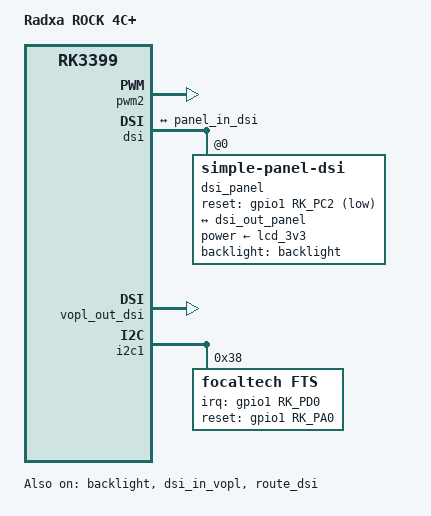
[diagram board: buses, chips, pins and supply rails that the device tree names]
/dts-v1/;
/plugin/;

#include <dt-bindings/gpio/gpio.h>
#include <dt-bindings/pinctrl/rockchip.h>
#include <dt-bindings/display/drm_mipi_dsi.h>
#include <dt-bindings/interrupt-controller/irq.h>

/ {
	model = "Radxa ROCK 4C+";
	compatible = "radxa,rock-4c-plus", "rockchip,rk3399";

	fragment@0 {
		target = <&backlight>;

		__overlay__ {
			status = "okay";
		};
	};

	fragment@1 {
		target = <&pwm2>;

		__overlay__ {
			status = "okay";
		};
	};

	fragment@2 {
		target = <&dsi>;

		__overlay__ {
			status = "okay";
			rockchip,lane-rate = <480>;
			#address-cells = <1>;
			#size-cells = <0>;

			ports {
				#address-cells = <1>;
				#size-cells = <0>;

				port@1 {
					reg = <1>;
					dsi_out_panel: endpoint {
						remote-endpoint = <&panel_in_dsi>;
					};
				};
			};

			dsi_panel: dsi-panel@0 {
				status = "okay";

				compatible = "simple-panel-dsi";
				reg = <0>;

				backlight = <&backlight>;
				power-supply = <&lcd_3v3>;

				reset-gpios = <&gpio1 RK_PC2 GPIO_ACTIVE_LOW>;

				pinctrl-names = "default";
				pinctrl-0 = <&lcd_panel_reset>;

				prepare-delay-ms = <120>;
				reset-delay-ms = <120>;
				init-delay-ms = <120>;
				enable-delay-ms = <100>;
				disable-delay-ms = <120>;
				unprepare-delay-ms = <120>;

				width-mm = <62>;
				height-mm = <110>;

				dsi,flags = <(MIPI_DSI_MODE_VIDEO | MIPI_DSI_MODE_VIDEO_BURST |
						MIPI_DSI_MODE_LPM | MIPI_DSI_MODE_EOT_PACKET)>;
				dsi,format = <MIPI_DSI_FMT_RGB888>;
				dsi,lanes = <4>;

				panel-init-sequence = [
					15 00 02 E0 00
					15 00 02 E1 93
					15 00 02 E2 65
					15 00 02 E3 F8
					15 00 02 80 03
					15 00 02 E0 01
					15 00 02 00 00
					15 00 02 01 3B
					15 00 02 0C 74
					15 00 02 17 00
					15 00 02 18 AF
					15 00 02 19 00
					15 00 02 1A 00
					15 00 02 1B AF
					15 00 02 1C 00
					15 00 02 35 26
					15 00 02 37 09
					15 00 02 38 04
					15 00 02 39 00
					15 00 02 3A 01
					15 00 02 3C 78
					15 00 02 3D FF
					15 00 02 3E FF
					15 00 02 3F 7F
					15 00 02 40 06
					15 00 02 41 A0
					15 00 02 42 81
					15 00 02 43 14
					15 00 02 44 23
					15 00 02 45 28
					15 00 02 55 02
					15 00 02 57 69
					15 00 02 59 0A
					15 00 02 5A 2A
					15 00 02 5B 17
					15 00 02 5D 7F
					15 00 02 5E 6B
					15 00 02 5F 5C
					15 00 02 60 4F
					15 00 02 61 4D
					15 00 02 62 3F
					15 00 02 63 42
					15 00 02 64 2B
					15 00 02 65 44
					15 00 02 66 43
					15 00 02 67 43
					15 00 02 68 63
					15 00 02 69 52
					15 00 02 6A 5A
					15 00 02 6B 4F
					15 00 02 6C 4E
					15 00 02 6D 20
					15 00 02 6E 0F
					15 00 02 6F 00
					15 00 02 70 7F
					15 00 02 71 6B
					15 00 02 72 5C
					15 00 02 73 4F
					15 00 02 74 4D
					15 00 02 75 3F
					15 00 02 76 42
					15 00 02 77 2B
					15 00 02 78 44
					15 00 02 79 43
					15 00 02 7A 43
					15 00 02 7B 63
					15 00 02 7C 52
					15 00 02 7D 5A
					15 00 02 7E 4F
					15 00 02 7F 4E
					15 00 02 80 20
					15 00 02 81 0F
					15 00 02 82 00
					15 00 02 E0 02
					15 00 02 00 02
					15 00 02 01 02
					15 00 02 02 00
					15 00 02 03 00
					15 00 02 04 1E
					15 00 02 05 1E
					15 00 02 06 1F
					15 00 02 07 1F
					15 00 02 08 1F
					15 00 02 09 17
					15 00 02 0A 17
					15 00 02 0B 37
					15 00 02 0C 37
					15 00 02 0D 47
					15 00 02 0E 47
					15 00 02 0F 45
					15 00 02 10 45
					15 00 02 11 4B
					15 00 02 12 4B
					15 00 02 13 49
					15 00 02 14 49
					15 00 02 15 1F
					15 00 02 16 01
					15 00 02 17 01
					15 00 02 18 00
					15 00 02 19 00
					15 00 02 1A 1E
					15 00 02 1B 1E
					15 00 02 1C 1F
					15 00 02 1D 1F
					15 00 02 1E 1F
					15 00 02 1F 17
					15 00 02 20 17
					15 00 02 21 37
					15 00 02 22 37
					15 00 02 23 46
					15 00 02 24 46
					15 00 02 25 44
					15 00 02 26 44
					15 00 02 27 4A
					15 00 02 28 4A
					15 00 02 29 48
					15 00 02 2A 48
					15 00 02 2B 1F
					15 00 02 2C 01
					15 00 02 2D 01
					15 00 02 2E 00
					15 00 02 2F 00
					15 00 02 30 1F
					15 00 02 31 1F
					15 00 02 32 1E
					15 00 02 33 1E
					15 00 02 34 1F
					15 00 02 35 17
					15 00 02 36 17
					15 00 02 37 37
					15 00 02 38 37
					15 00 02 39 08
					15 00 02 3A 08
					15 00 02 3B 0A
					15 00 02 3C 0A
					15 00 02 3D 04
					15 00 02 3E 04
					15 00 02 3F 06
					15 00 02 40 06
					15 00 02 41 1F
					15 00 02 42 02
					15 00 02 43 02
					15 00 02 44 00
					15 00 02 45 00
					15 00 02 46 1F
					15 00 02 47 1F
					15 00 02 48 1E
					15 00 02 49 1E
					15 00 02 4A 1F
					15 00 02 4B 17
					15 00 02 4C 17
					15 00 02 4D 37
					15 00 02 4E 37
					15 00 02 4F 09
					15 00 02 50 09
					15 00 02 51 0B
					15 00 02 52 0B
					15 00 02 53 05
					15 00 02 54 05
					15 00 02 55 07
					15 00 02 56 07
					15 00 02 57 1F
					15 00 02 58 40
					15 00 02 5B 30
					15 00 02 5C 16
					15 00 02 5D 34
					15 00 02 5E 05
					15 00 02 5F 02
					15 00 02 63 00
					15 00 02 64 6A
					15 00 02 67 73
					15 00 02 68 1D
					15 00 02 69 08
					15 00 02 6A 6A
					15 00 02 6B 08
					15 00 02 6C 00
					15 00 02 6D 00
					15 00 02 6E 00
					15 00 02 6F 88
					15 00 02 75 FF
					15 00 02 77 DD
					15 00 02 78 3F
					15 00 02 79 15
					15 00 02 7A 17
					15 00 02 7D 14
					15 00 02 7E 82
					15 00 02 E0 04
					15 00 02 00 0E
					15 00 02 02 B3
					15 00 02 09 61
					15 00 02 0E 48
					15 00 02 E0 00
					15 00 02 E6 02
					15 00 02 E7 0C
					05 78 01 11
					05 14 01 29
				];

				panel-exit-sequence = [
					05 14 01 28
					05 78 01 10
				];

				display-timings {
					native-mode = <&timing0>;
					timing0: timing0 {
						clock-frequency = <67000000>;
						hactive = <800>;
						vactive = <1280>;

						vback-porch = <20>;
						vfront-porch = <20>;

						hback-porch = <20>;
						hfront-porch = <40>;

						hsync-len = <18>;
						vsync-len = <4>;

						vsync-active = <0>;
						hsync-active = <0>;
						de-active = <0>;
						pixelclk-active = <0>;
					};
				};

				ports {
					#address-cells = <1>;
					#size-cells = <0>;

					port@0 {
						reg = <0>;
						panel_in_dsi: endpoint {
							remote-endpoint = <&dsi_out_panel>;
						};
					};
				};
			};
		};
	};

	fragment@3 {
		target = <&vopl_out_dsi>;

		__overlay__ {
			status = "okay";
		};
	};

	fragment@4 {
		target = <&dsi_in_vopl>;

		__overlay__ {
			status = "okay";
		};
	};

	fragment@5 {
		target = <&route_dsi>;

		__overlay__ {
			status = "okay";
			connect = <&vopl_out_dsi>;
		};
	};

	fragment@6 {
		target = <&i2c1>;

		__overlay__ {
			status = "okay";
			#address-cells = <1>;
			#size-cells = <0>;

			focaltech: focaltech@38 {
				status = "okay";
				compatible = "focaltech,fts";
				reg = <0x38>;
				pinctrl-names = "default";
				pinctrl-0 = <&touch_gpio>;
				focaltech,irq-gpio = <&gpio1 RK_PD0 IRQ_TYPE_LEVEL_LOW>;
				focaltech,reset-gpio = <&gpio1 RK_PA0 GPIO_ACTIVE_HIGH>;
				focaltech,have-key = <0>;
				focaltech,key-number = <3>;
				focaltech,keys = <256 1068 64 64 128 1068 64 64 192 1068 64 64>;
				focaltech,key-x-coord = <800>;
				focaltech,key-y-coord = <1280>;
				focaltech,max-touch-number = <5>;
			};
		};
	};

	fragment@7 {
		target = <&cdn_dp>;

		__overlay__ {
			status = "disabled";
		};
	};

	fragment@8 {
		target = <&tcphy0>;

		__overlay__ {
			status = "disabled";
		};
	};

	fragment@9 {
		target = <&dp_in_vopl>;

		__overlay__ {
			status = "disabled";
		};
	};

	fragment@10 {
		target = <&tcphy0_dp>;

		__overlay__ {
			status = "disabled";
		};
	};

	fragment@11 {
		target = <&tcphy0_usb3>;

		__overlay__ {
			status = "disabled";
		};
	};
};
